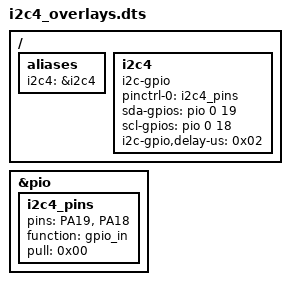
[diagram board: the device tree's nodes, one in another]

&pio {
	i2c4_pins: i2c4_pins {
		pins = "PA19", "PA18";
		function = "gpio_in";
		pull = <0x00>;
	};
};

/ {
	aliases {
		i2c4 = &i2c4;
	};

	i2c4: i2c4 {
		compatible = "i2c-gpio";
		pinctrl-0 = <&i2c4_pins>;
		pinctrl-names = "default";
		sda-gpios = <&pio 0 19 6>;
		scl-gpios = <&pio 0 18 6>;
		i2c-gpio,delay-us = <0x02>;
		status = "okay";
	};
};


